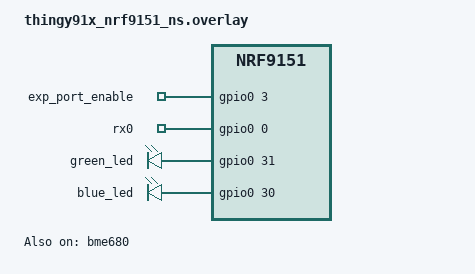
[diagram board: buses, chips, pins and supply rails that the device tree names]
/*
 * Copyright (c) 2022 Achim Kraus CloudCoap.net
 *
 * See the NOTICE file(s) distributed with this work for additional
 * information regarding copyright ownership.
 *
 * This program and the accompanying materials are made available under the
 * terms of the Eclipse Public License 2.0 which is available at
 * http: //www.eclipse.org/legal/epl-2.0
 *
 * SPDX-License-Identifier: EPL-2.0
 */

/ {

	outs {
		compatible = "gpio-leds";
		status = "okay";
		
		exp_port_enable: exp_port_enable {
			gpios = <&gpio0 3 GPIO_ACTIVE_HIGH>;
		};

	};

	ins {
		compatible = "gpio-keys";
		rx0: uart0_rx {
			gpios = <&gpio0 0 0>;
		};
	};

	/*
	 * Map the devices to the aliases of the application.
	 */
	aliases {
		/* alias for sensor with SENSOR_CHAN_AMBIENT_TEMP channel */
		temperature-sensor = &bme680;
		/* alias for sensor with SENSOR_CHAN_HUMIDITY channel */
		humidity-sensor = &bme680;
		/* alias for sensor with SENSOR_CHAN_PRESS channel */
		pressure-sensor = &bme680;
		/* alias for sensor with SENSOR_CHAN_GAS_RES channel */
		gas-sensor = &bme680;

		/* alias for BME680 sensor to be used with Bosch BSEC library (IAQ Index Air Quality) */
		environment-sensor = &bme680;

		/* alias for watchdog */
		watchdog0 = &wdt0;

		exp-port-enable = &exp_port_enable;

	};

};

&green_led {
	gpios = <&gpio0 31 0>;
};

&blue_led {
	gpios = <&gpio0 30 0>;
};


&bme680 {
	status = "okay";
};

&flash_ext {
	jedec-id = [c8 60 19];
};


sensor_i2c: &i2c2 { };
